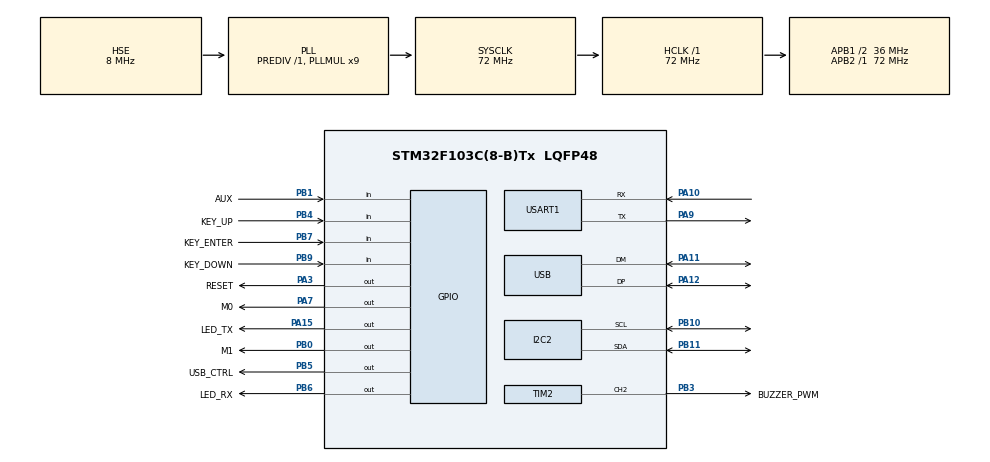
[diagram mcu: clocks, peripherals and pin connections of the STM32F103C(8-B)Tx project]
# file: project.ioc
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I2C2.I2C_Mode=I2C_Fast
Mcu.Family=STM32F1
Mcu.Name=STM32F103C(8-B)Tx
Mcu.Package=LQFP48
NVIC.PriorityGroup=NVIC_PRIORITYGROUP_4
NVIC.USART1_IRQn=true\:0\:0\:false\:false\:true\:true\:true\:true
NVIC.USB_LP_CAN1_RX0_IRQn=true\:0\:0\:false\:false\:true\:false\:true\:true
PA10.Mode=Asynchronous
PA10.Signal=USART1_RX
PA11.Mode=Device
PA11.Signal=USB_DM
PA12.Mode=Device
PA12.Signal=USB_DP
PA13.Mode=Serial_Wire
PA13.Signal=SYS_JTMS-SWDIO
PA14.Mode=Serial_Wire
PA14.Signal=SYS_JTCK-SWCLK
PA15.GPIO_Label=LED_TX
PA15.PinState=GPIO_PIN_SET
PA15.Signal=GPIO_Output
PA3.GPIO_Label=RESET
PA3.PinState=GPIO_PIN_SET
PA3.Signal=GPIO_Output
PA7.GPIO_Label=M0
PA7.PinState=GPIO_PIN_SET
PA7.Signal=GPIO_Output
PA9.Mode=Asynchronous
PA9.Signal=USART1_TX
PB0.GPIO_Label=M1
PB0.PinState=GPIO_PIN_SET
PB0.Signal=GPIO_Output
PB1.GPIO_Label=AUX
PB1.GPIO_PuPd=GPIO_PULLUP
PB1.Signal=GPIO_Input
PB10.Mode=I2C
PB10.Signal=I2C2_SCL
PB11.Mode=I2C
PB11.Signal=I2C2_SDA
PB3.GPIO_Label=BUZZER_PWM
PB3.Signal=S_TIM2_CH2
PB4.GPIO_Label=KEY_UP
PB4.Signal=GPIO_Input
PB5.GPIO_Label=USB_CTRL
PB5.Signal=GPIO_Output
PB6.GPIO_Label=LED_RX
PB6.PinState=GPIO_PIN_SET
PB6.Signal=GPIO_Output
PB7.GPIO_Label=KEY_ENTER
PB7.Signal=GPIO_Input
PB9.GPIO_Label=KEY_DOWN
PB9.Signal=GPIO_Input
PC14-OSC32_IN.Mode=LSE-External-Oscillator
PC14-OSC32_IN.Signal=RCC_OSC32_IN
PC15-OSC32_OUT.Mode=LSE-External-Oscillator
PC15-OSC32_OUT.Signal=RCC_OSC32_OUT
PD0-OSC_IN.Mode=HSE-External-Oscillator
PD0-OSC_IN.Signal=RCC_OSC_IN
PD1-OSC_OUT.Mode=HSE-External-Oscillator
PD1-OSC_OUT.Signal=RCC_OSC_OUT
ProjectManager.HeapSize=0x200
ProjectManager.StackSize=0x400
ProjectManager.TargetToolchain=Makefile
RCC.AHBFreq_Value=72000000
RCC.APB1CLKDivider=RCC_HCLK_DIV2
RCC.APB1Freq_Value=36000000
RCC.APB1TimFreq_Value=72000000
RCC.APB2Freq_Value=72000000
RCC.APB2TimFreq_Value=72000000
RCC.HCLKFreq_Value=72000000
RCC.PLLMUL=RCC_PLL_MUL9
RCC.SYSCLKFreq_VALUE=72000000
RCC.SYSCLKSource=RCC_SYSCLKSOURCE_PLLCLK
RCC.USBFreq_Value=48000000
RCC.USBPrescaler=RCC_USBCLKSOURCE_PLL_DIV1_5
SH.S_TIM2_CH2.0=TIM2_CH2,PWM Generation2 CH2
TIM2.AutoReloadPreload=TIM_AUTORELOAD_PRELOAD_ENABLE
TIM2.Channel-PWM\ Generation2\ CH2=TIM_CHANNEL_2
TIM2.Period=300-1
TIM2.Prescaler=72-1
TIM2.Pulse-PWM\ Generation2\ CH2=150-1
USART1.VirtualMode=VM_ASYNC
USB_DEVICE.CLASS_NAME_FS=CDC
USB_DEVICE.VirtualMode=Cdc
USB_DEVICE.VirtualModeFS=Cdc_FS
VP_USB_DEVICE_VS_USB_DEVICE_CDC_FS.Mode=CDC_FS
board=custom

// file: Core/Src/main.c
/* USER CODE BEGIN Header */
/**
  ******************************************************************************
  * @file           : main.c
  * @brief          : Main program body
  ******************************************************************************
  * @attention
  *
  * Copyright (c) 2024 STMicroelectronics.
  * All rights reserved.
  *
  * This software is licensed under terms that can be found in the LICENSE file
  * in the root directory of this software component.
  * If no LICENSE file comes with this software, it is provided AS-IS.
  *
  ******************************************************************************
  */
/* USER CODE END Header */
#include "main.h"
#include "i2c.h"
#include "tim.h"
#include "usart.h"
#include "usb_device.h"
#include "gpio.h"

/* USER CODE BEGIN Includes */
#include "e22_hal.h"
/* USER CODE END Includes */

/* USER CODE BEGIN PD */
#include "usbd_cdc_if.h"
extern uint8_t usb_rx_data;
/* USER CODE END PD */

void SystemClock_Config(void);

int main(void)
{

  /* MCU Configuration--------------------------------------------------------*/

  /* Reset of all peripherals, Initializes the Flash interface and the Systick. */
  HAL_Init();

  /* Configure the system clock */
  SystemClock_Config();

  /* Initialize all configured peripherals */
  MX_GPIO_Init();
  e22_hal_work_mode(WORK_MODE_TRANSPARENT);
  MX_I2C2_Init();
  MX_USART1_UART_Init();
  MX_USB_DEVICE_Init();
  MX_TIM2_Init();
  /* USER CODE BEGIN 2 */
  HAL_UART_Receive_IT(&huart1, &usb_rx_data, 1);
	/* �˵���ʼ�� */
	Menu_Init();

  /* USER CODE END 2 */

  /* Infinite loop */
  while (1)
  {

    /* USER CODE BEGIN 3 */

		/* �˵���Ӧ */
		Menu_Task();
		usb_receive_to_tx_send();
			usart_fifo_flush_to_cdc();
  }
  /* USER CODE END 3 */
}

void SystemClock_Config(void)
{
  RCC_OscInitTypeDef RCC_OscInitStruct = {0};
  RCC_ClkInitTypeDef RCC_ClkInitStruct = {0};
  RCC_PeriphCLKInitTypeDef PeriphClkInit = {0};

  /** Initializes the RCC Oscillators according to the specified parameters
  * in the RCC_OscInitTypeDef structure.
  */
  RCC_OscInitStruct.OscillatorType = RCC_OSCILLATORTYPE_HSE;
  RCC_OscInitStruct.HSEState = RCC_HSE_ON;
  RCC_OscInitStruct.HSEPredivValue = RCC_HSE_PREDIV_DIV1;
  RCC_OscInitStruct.HSIState = RCC_HSI_ON;
  RCC_OscInitStruct.PLL.PLLState = RCC_PLL_ON;
  RCC_OscInitStruct.PLL.PLLSource = RCC_PLLSOURCE_HSE;
  RCC_OscInitStruct.PLL.PLLMUL = RCC_PLL_MUL9;
  if (HAL_RCC_OscConfig(&RCC_OscInitStruct) != HAL_OK)
  {
    Error_Handler();
  }

  /** Initializes the CPU, AHB and APB buses clocks
  */
  RCC_ClkInitStruct.ClockType = RCC_CLOCKTYPE_HCLK|RCC_CLOCKTYPE_SYSCLK
                              |RCC_CLOCKTYPE_PCLK1|RCC_CLOCKTYPE_PCLK2;
  RCC_ClkInitStruct.SYSCLKSource = RCC_SYSCLKSOURCE_PLLCLK;
  RCC_ClkInitStruct.AHBCLKDivider = RCC_SYSCLK_DIV1;
  RCC_ClkInitStruct.APB1CLKDivider = RCC_HCLK_DIV2;
  RCC_ClkInitStruct.APB2CLKDivider = RCC_HCLK_DIV1;

  if (HAL_RCC_ClockConfig(&RCC_ClkInitStruct, FLASH_LATENCY_2) != HAL_OK)
  {
    Error_Handler();
  }
  PeriphClkInit.PeriphClockSelection = RCC_PERIPHCLK_USB;
  PeriphClkInit.UsbClockSelection = RCC_USBCLKSOURCE_PLL_DIV1_5;
  if (HAL_RCCEx_PeriphCLKConfig(&PeriphClkInit) != HAL_OK)
  {
    Error_Handler();
  }
}

void Error_Handler(void)
{
  __disable_irq();
  while (1)
  {
  }
}

#ifdef  USE_FULL_ASSERT
/**
  * @brief  Reports the name of the source file and the source line number
  *         where the assert_param error has occurred.
  * @param  file: pointer to the source file name
  * @param  line: assert_param error line source number
  * @retval None
  */
void assert_failed(uint8_t *file, uint32_t line)
{
  /* USER CODE BEGIN 6 */
  /* User can add his own implementation to report the file name and line number,
     ex: usb_printf("Wrong parameters value: file %s on line %d\r\n", file, line) */
  /* USER CODE END 6 */
}
#endif /* USE_FULL_ASSERT */
